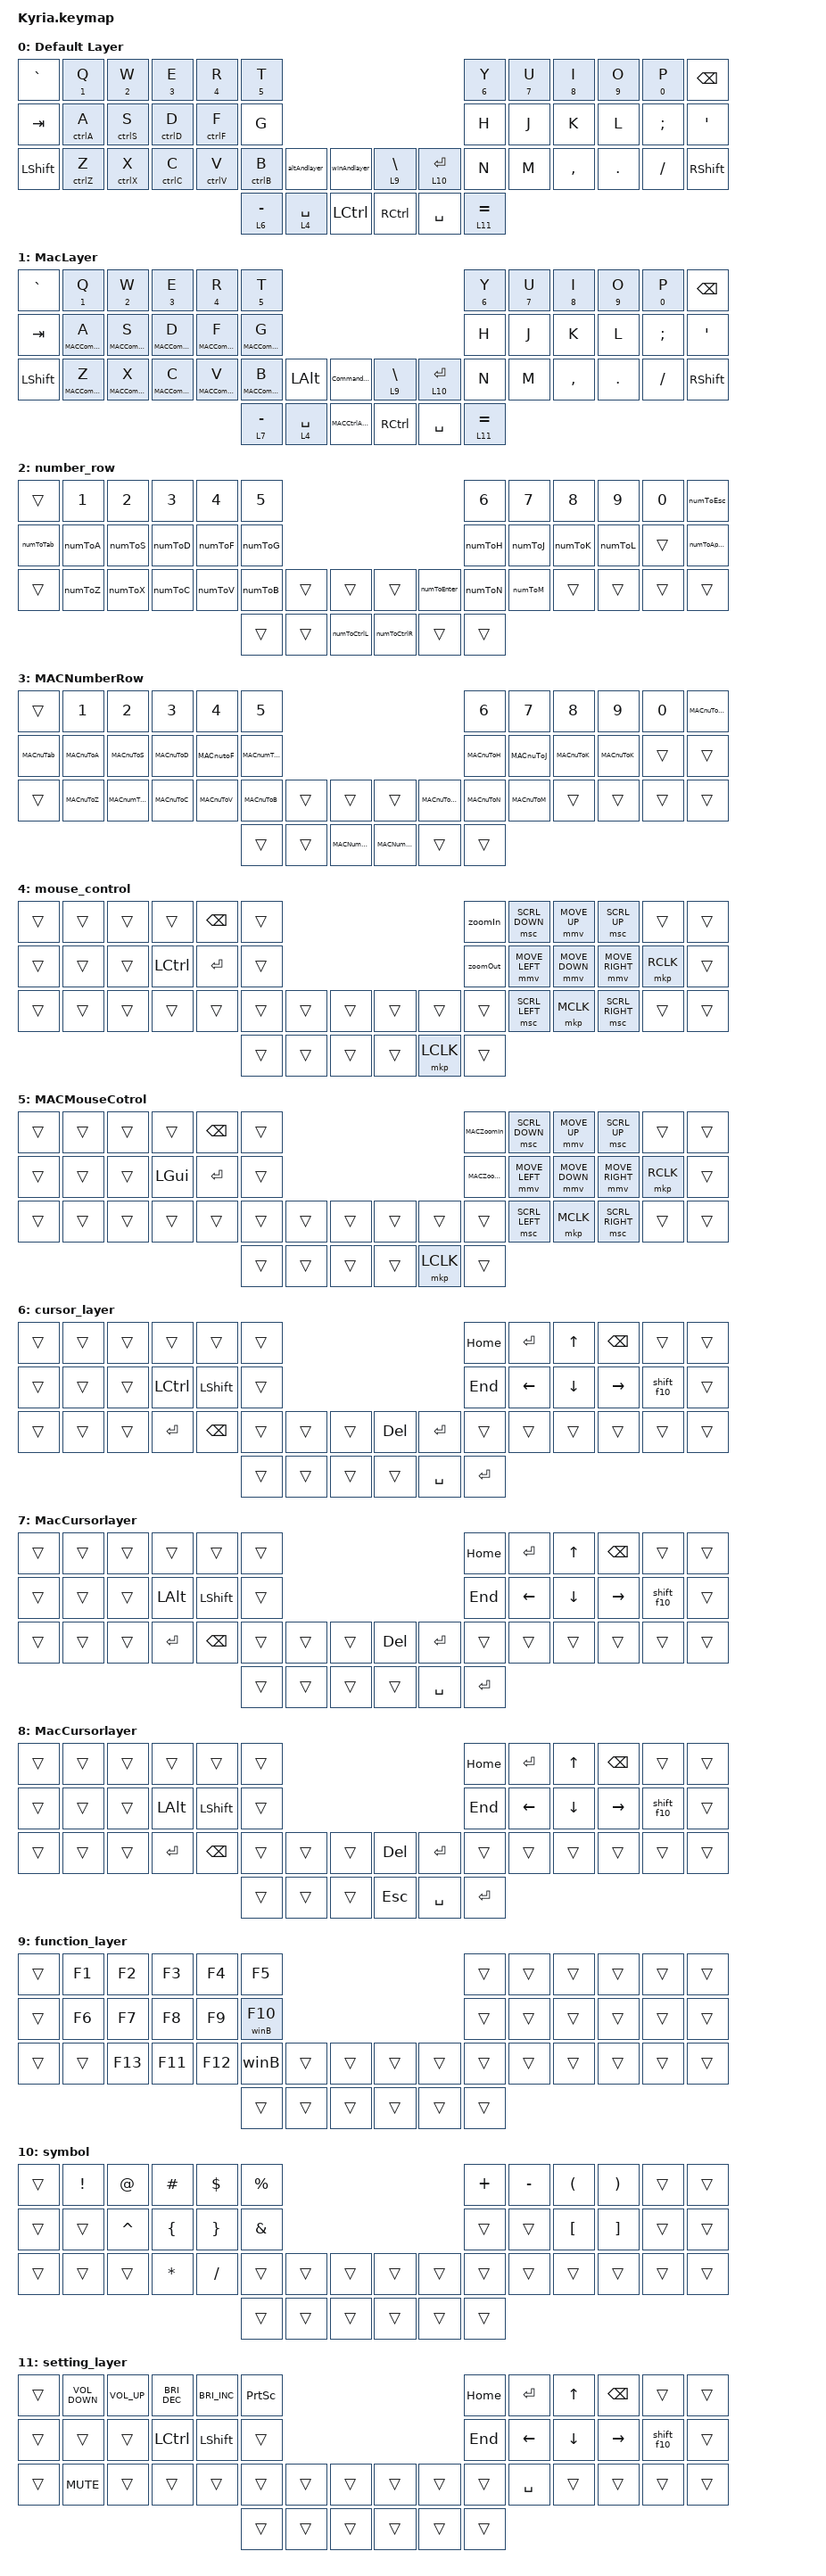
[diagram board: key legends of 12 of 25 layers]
/*
 * Copyright (c) 2020 The ZMK Contributors
 *
 * SPDX-License-Identifier: MIT
 */

#include <input/processors.dtsi>
#include <zephyr/dt-bindings/input/input-event-codes.h>
#include <dt-bindings/zmk/mouse.h>
#include <behaviors/mouse_keys.dtsi>
#include <behaviors.dtsi>
#include <dt-bindings/zmk/bt.h>
#include <dt-bindings/zmk/keys.h>
#include <dt-bindings/zmk/pointing.h>

#define ZMK_POINTING_DEFAULT_MOVE_VAL 1200  // 600
#define ZMK_POINTING_DEFAULT_SCRL_VAL 300   // mousescroll SPEED

&mmv_input_listener { input-processors = <&zip_xy_scaler 2 1>; };

&msc_input_listener { input-processors = <&zip_scroll_scaler 2 1>; };

&msc {
    acceleration-exponent = <1>;      // 0
    time-to-max-speed-ms = <3000>;       // 300
    delay-ms = <0>;                   // 0
};

&mmv {
    time-to-max-speed-ms = <1000>;
    acceleration-exponent = <1>;
    trigger-period-ms = <16>;
};

&soft_off {
    hold-time-ms = <3000>; // Only turn off it the key is held for 3 seconds or longer.
};

&mt { flavor = "tap-preferred"; };

&lt {
    tapping-term-ms = <300>;
    flavor = "balanced";
};

&sk {
    quick-release;
    lazy;
};

/ {
    behaviors {
        Scroll_D_U: Scroll_D_U {
            compatible = "zmk,behavior-sensor-rotate";
            label = "SCROLL_D_U";
            #sensor-binding-cells = <0>;
            bindings = <&msc SCRL_DOWN>, <&msc SCRL_UP>;

            tap-ms = <20>;
        };

        TD01: TD01 {
            compatible = "zmk,behavior-tap-dance";
            label = "TD01";
            #binding-cells = <0>;
            bindings = <&kp MINUS>, <&kp PERIOD>;
        };

        Scroll_U_D: Scroll_U_D {
            compatible = "zmk,behavior-sensor-rotate";
            label = "SCROLL_U_D";
            #sensor-binding-cells = <0>;
            bindings = <&msc SCRL_UP>, <&msc SCRL_DOWN>;

            tap-ms = <20>;
        };

        Scroll_LR: Scroll_LR {
            compatible = "zmk,behavior-sensor-rotate";
            label = "SCROLL_LR";
            #sensor-binding-cells = <0>;
            bindings = <&msc SCRL_LEFT>, <&msc SCRL_RIGHT>;

            tap-ms = <20>;
        };

        Scroll_RL: Scroll_RL {
            compatible = "zmk,behavior-sensor-rotate";
            label = "SCROLL_RL";
            #sensor-binding-cells = <0>;
            bindings = <&msc SCRL_RIGHT>, <&msc SCRL_LEFT>;

            tap-ms = <20>;
        };

        mouse_DU: mouse_DU {
            compatible = "zmk,behavior-sensor-rotate";
            label = "MOUSE_DU";
            #sensor-binding-cells = <0>;
            bindings = <&mmv MOVE_DOWN>, <&mmv MOVE_UP>;
        };

        mouse_RL: mouse_RL {
            compatible = "zmk,behavior-sensor-rotate";
            label = "MOUSE_RL";
            #sensor-binding-cells = <0>;
            bindings = <&mmv MOVE_RIGHT>, <&mmv MOVE_LEFT>;
        };

        cursorandmouse: cursorandmouse_ {
            compatible = "zmk,behavior-tap-dance";
            label = "CURSORANDMOUSE ";
            #binding-cells = <0>;
            bindings = <&lt 22 SPACE>, <&lt 2 SPACE>;

            tapping-term-ms = <400>;
        };

        num_row: num_row {
            compatible = "zmk,behavior-hold-tap";
            label = "NUM_ROW";
            bindings = <&kp>, <&kp>;

            #binding-cells = <2>;
            tapping-term-ms = <300>;
            flavor = "tap-preferred";
        };

        holdCtrlZ: holdCtrlZ {
            compatible = "zmk,behavior-hold-tap";
            label = "HOLDCTRLZ";
            bindings = <&ctrlZ>, <&kp>;

            #binding-cells = <2>;
            tapping-term-ms = <300>;
            flavor = "tap-preferred";
        };

        holdCtrlX: holdCtrlX {
            compatible = "zmk,behavior-hold-tap";
            label = "HOLDCTRLX";
            bindings = <&ctrlX>, <&kp>;

            #binding-cells = <2>;
            tapping-term-ms = <300>;
            flavor = "tap-preferred";
        };

        holdCtrlC: holdCtrlC {
            compatible = "zmk,behavior-hold-tap";
            label = "HOLDCTRLC";
            bindings = <&ctrlC>, <&kp>;

            #binding-cells = <2>;
            tapping-term-ms = <300>;
            flavor = "tap-preferred";
        };

        holdCtrlA: holdCtrlA {
            compatible = "zmk,behavior-hold-tap";
            label = "HOLDCTRLA";
            bindings = <&ctrlA>, <&kp>;

            #binding-cells = <2>;
            tapping-term-ms = <300>;
            flavor = "tap-preferred";
        };

        shiftCtrlTapDance: shiftCtrlTapDance {
            compatible = "zmk,behavior-tap-dance";
            label = "SHIFTCTRLTAPDANCE";
            #binding-cells = <0>;
            bindings = <&kp LEFT_SHIFT>, <&kp LCTRL>;
        };

        shiftEnterTapDance: shiftEnterTapDance {
            compatible = "zmk,behavior-tap-dance";
            label = "SHIFTENTERTAPDANCE";
            #binding-cells = <0>;
            bindings = <&kp RIGHT_SHIFT>, <&kp ENTER>;
        };

        cursorLayerTap: cursorLayerTap {
            compatible = "zmk,behavior-hold-tap";
            label = "CURSORLAYERTAP";
            bindings = <&mo>, <&kp>;

            #binding-cells = <2>;
            tapping-term-ms = <200>;
            flavor = "hold-preferred";
            hold-trigger-key-positions = <32 43 44 33 45 7 8 9 10 11 19 20 21 22 23 35 36 37 38 39 45 6 7 18 19 34 35 14 15 16>;
        };

        WinKey: WinKey {
            compatible = "zmk,behavior-tap-dance";
            label = "WINKEY";
            #binding-cells = <0>;
            bindings = <&winAndlayer>, <&winTabCom>;

            tapping-term-ms = <300>;
        };

        LBracketTapDance: LBracketTapDance {
            compatible = "zmk,behavior-tap-dance";
            label = "LBRACKETTAPDANCE";
            #binding-cells = <0>;
            bindings = <&kp LEFT_BRACKET>, <&kp LEFT_BRACE>;

            tapping-term-ms = <600>;
        };

        RBracketTapDance: RBracketTapDance {
            compatible = "zmk,behavior-tap-dance";
            label = "RBRACKETTAPDANCE";
            #binding-cells = <0>;
            bindings = <&kp LEFT_BRACKET>, <&kp RIGHT_BRACE>;

            tapping-term-ms = <600>;
        };

        F10WinB: F10WinB {
            compatible = "zmk,behavior-hold-tap";
            label = "F10WINB";
            bindings = <&winB>, <&kp>;

            #binding-cells = <2>;
            tapping-term-ms = <200>;
        };

        holdCtrlS: holdCtrlS {
            compatible = "zmk,behavior-hold-tap";
            label = "HOLDCTRLS";
            bindings = <&ctrlS>, <&kp>;

            #binding-cells = <2>;
            tapping-term-ms = <300>;
            flavor = "tap-preferred";
        };

        holdCtrlV: holdCtrlV {
            compatible = "zmk,behavior-hold-tap";
            label = "HOLDCTRLV";
            bindings = <&ctrlV>, <&kp>;

            #binding-cells = <2>;
            tapping-term-ms = <300>;
            flavor = "tap-preferred";
        };

        symbolLayertap: symbolLayertap {
            compatible = "zmk,behavior-hold-tap";
            label = "SYMBOLLAYERTAP";
            bindings = <&mo>, <&kp>;

            #binding-cells = <2>;
            tapping-term-ms = <200>;
            hold-trigger-key-positions = <1 2 3 4 5 16 15 19 18 6 7 8 20 9 21 27 28 14 17>;
            flavor = "balanced";
        };

        holdCtrlF: holdCtrlF {
            compatible = "zmk,behavior-hold-tap";
            label = "HOLDCTRLF";
            bindings = <&ctrlF>, <&kp>;

            #binding-cells = <2>;
            tapping-term-ms = <300>;
            flavor = "tap-preferred";
        };

        holdCtrlD: holdCtrlD {
            compatible = "zmk,behavior-hold-tap";
            label = "HOLDCTRLD";
            bindings = <&ctrlD>, <&kp>;

            #binding-cells = <2>;
            tapping-term-ms = <300>;
            flavor = "tap-preferred";
        };

        mouseLayerTap: mouseLayerTap {
            compatible = "zmk,behavior-hold-tap";
            label = "MOUSELAYERTAP";
            bindings = <&mo>, <&kp>;

            #binding-cells = <2>;
            tapping-term-ms = <200>;
            hold-trigger-key-positions = <16 1 2 3 4 13 14 15 16 25 26 27 28>;
            flavor = "balanced";
        };

        altLayerBehave: altLayerBehave {
            compatible = "zmk,behavior-hold-tap";
            label = "ALTLAYERBEHAVE";
            bindings = <&altAndlayer>, <&kp>;

            #binding-cells = <2>;
            tapping-term-ms = <200>;
            hold-trigger-key-positions = <3 4 2>;
            flavor = "balanced";
        };

        holdCtrlB: holdCtrlB {
            compatible = "zmk,behavior-hold-tap";
            label = "HOLDCTRLB";
            bindings = <&ctrlB>, <&kp>;

            #binding-cells = <2>;
            tapping-term-ms = <300>;
            flavor = "tap-preferred";
        };

        functionLayerTap: functionLayerTap {
            compatible = "zmk,behavior-hold-tap";
            label = "FUNCTIONLAYERTAP";
            bindings = <&mo>, <&kp>;

            #binding-cells = <2>;
            tapping-term-ms = <200>;
            hold-trigger-key-positions = <1 2 3 4 13 14 15 16 25 26 27 28 16 17 28 29 5>;
            flavor = "hold-preferred";
        };

        MACHoldCommandA: MACHoldCommandA {
            compatible = "zmk,behavior-hold-tap";
            label = "MACHOLDCOMMANDA";
            bindings = <&MACCommandA>, <&kp>;

            #binding-cells = <2>;
            tapping-term-ms = <300>;
            flavor = "tap-preferred";
        };

        MACHoldCommandZ: MACHoldCommandZ {
            compatible = "zmk,behavior-hold-tap";
            label = "MACHOLDCOMMANDZ";
            bindings = <&MACCommandZ>, <&kp>;

            #binding-cells = <2>;
            tapping-term-ms = <300>;
            flavor = "tap-preferred";
        };

        MACHoldCommandS: MACHoldCommandS {
            compatible = "zmk,behavior-hold-tap";
            label = "MACHOLDCOMMANDS";
            bindings = <&MACCommandS>, <&kp>;

            #binding-cells = <2>;
            tapping-term-ms = <300>;
            flavor = "tap-preferred";
        };

        MACHoldCommandX: MACHoldCommandX {
            compatible = "zmk,behavior-hold-tap";
            label = "MACHOLDCOMMANDX";
            bindings = <&MACCommandX>, <&kp>;

            #binding-cells = <2>;
            tapping-term-ms = <300>;
            flavor = "tap-preferred";
        };

        MACHoldCommandD: MACHoldCommandD {
            compatible = "zmk,behavior-hold-tap";
            label = "MACHOLDCOMMANDD";
            bindings = <&MACCommandD>, <&kp>;

            #binding-cells = <2>;
            tapping-term-ms = <300>;
            flavor = "tap-preferred";
        };

        MACHoldCommandC: MACHoldCommandC {
            compatible = "zmk,behavior-hold-tap";
            label = "MACHOLDCOMMANDC";
            bindings = <&MACCommandC>, <&kp>;

            #binding-cells = <2>;
            tapping-term-ms = <300>;
            flavor = "tap-preferred";
        };

        MACHoldCommandF: MACHoldCommandF {
            compatible = "zmk,behavior-hold-tap";
            label = "MACHOLDCOMMANDF";
            bindings = <&MACCommandF>, <&kp>;

            #binding-cells = <2>;
            tapping-term-ms = <300>;
            flavor = "tap-preferred";
        };

        MACHoldCommandV: MACHoldCommandV {
            compatible = "zmk,behavior-hold-tap";
            label = "MACHOLDCOMMANDV";
            bindings = <&MACCommandV>, <&kp>;

            #binding-cells = <2>;
            tapping-term-ms = <300>;
            flavor = "tap-preferred";
        };

        MACHoldCommandG: MACHoldCommandG {
            compatible = "zmk,behavior-hold-tap";
            label = "MACHOLDCOMMANDG";
            bindings = <&MACCommandG>, <&kp>;

            #binding-cells = <2>;
            tapping-term-ms = <300>;
            flavor = "tap-preferred";
        };

        MACHoldCommandB: MACHoldCommandB {
            compatible = "zmk,behavior-hold-tap";
            label = "MACHOLDCOMMANDB";
            bindings = <&MACCommandB>, <&kp>;

            #binding-cells = <2>;
            tapping-term-ms = <300>;
            flavor = "tap-preferred";
        };

        ToggleOnOnly: ToggleOnOnly {
            compatible = "zmk,behavior-toggle-layer";
            label = "TOGGLEONONLY";
            #binding-cells = <1>;
        };

        ToggleOffOnly: ToggleOffOnly {
            compatible = "zmk,behavior-toggle-layer";
            label = "TOGGLEOFFONLY";
            #binding-cells = <1>;
            toggle-mode = "off";
        };
    };

    combos {
        compatible = "zmk,combos";

        ctrl-shift-combo {
            bindings = <&ctrlShiftCombo>;
            key-positions = <24 25>;
            layers = <0 2 10>;
        };

        one-keyboard-control {
            bindings = <&to 22>;
            key-positions = <12 0>;
        };

        bt_cl_all {
            bindings = <&bt BT_CLR_ALL>;
            key-positions = <29 30>;
        };

        bt_next {
            bindings = <&bt BT_NXT>;
            key-positions = <43 33>;
            timeout-ms = <300>;
        };

        number_row_combo {
            bindings = <&tog 2>;
            key-positions = <16 19>;
            layers = <0 2>;
            require-prior-idle-ms = <150>;
        };

        toggle_mouse_L {
            bindings = <&tog 4>;
            key-positions = <40 41>;
            layers = <0 4>;
        };

        esc {
            bindings = <&numToEsc>;
            key-positions = <15 41>;
            timeout-ms = <400>;
            layers = <0 2 4>;
            slow-release;
            require-prior-idle-ms = <150>;
        };

        combo_left_shift {
            bindings = <&kp LEFT_SHIFT>;
            key-positions = <15 16>;
            timeout-ms = <200>;
            layers = <0 10 2 16 14 11 1 3>;
            require-prior-idle-ms = <150>;
        };

        combo_right_shift {
            bindings = <&kp RIGHT_SHIFT>;
            key-positions = <19 20>;
            timeout-ms = <200>;
            layers = <0 10 2 16 14 1 3>;
            require-prior-idle-ms = <150>;
        };

        capslook {
            bindings = <&kp CAPSLOCK>;
            key-positions = <15 20>;
            layers = <0 2 1 3>;
            require-prior-idle-ms = <150>;
        };

        firstP_gaming {
            bindings = <&tog 23>;
            key-positions = <12 24>;
            layers = <0 2 10 23>;
        };

        togKbMouse {
            bindings = <&tog 13>;
            key-positions = <42 31>;
            layers = <0 2 13 1 3>;
        };

        alt_tab_combo {
            bindings = <&alt_tab>;
            key-positions = <30 3>;
            layers = <0 2 6>;
        };

        altF4Combo {
            bindings = <&altF4d>;
            key-positions = <4 30>;
            layers = <0 2>;
        };

        winBCombo {
            bindings = <&winB>;
            key-positions = <31 29>;
            layers = <0 2>;
        };

        winTabCombo {
            bindings = <&winTabCom>;
            key-positions = <31 4>;
            layers = <0 14 1>;
        };

        bluetoothSetting {
            bindings = <&mo 24>;
            key-positions = <12 24>;
        };

        toMacLayerComb {
            bindings = <&tog 1>;
            key-positions = <29 40>;
            layers = <0 2>;
        };

        MACComboType {
            bindings = <&MACMacroType>;
            key-positions = <40 28>;
            layers = <1>;
        };

        WINComboType {
            bindings = <&WINMacroType>;
            key-positions = <40 28>;
            layers = <0>;
        };

        toWINLayerComb {
            bindings = <&to 0>;
            key-positions = <29 40>;
            layers = <1 3>;
        };

        MACNumberRowCombo {
            bindings = <&tog 3>;
            key-positions = <16 19>;
            layers = <1 3>;
        };

        MACEsc {
            bindings = <&MACNumToEsc>;
            key-positions = <15 41>;
            timeout-ms = <400>;
            slow-release;
            layers = <1 3 5>;
        };

        EnterComb {
            bindings = <&kp ENTER>;
            key-positions = <20 44>;
            layers = <0 2 4 6 1 3 5 7>;
            slow-release;
            require-prior-idle-ms = <150>;
        };

        MACMouseControlL {
            bindings = <&tog 5>;
            key-positions = <41 40>;
            layers = <1 5>;
        };

        toggle_mouse_control_r {
            bindings = <&tog 4>;
            key-positions = <44 45>;
            layers = <0 4>;
        };

        MACMouseControlR {
            bindings = <&tog 5>;
            key-positions = <44 45>;
            layers = <1 5>;
        };
    };

    macros {
        alt_tab: alt_tab {
            compatible = "zmk,behavior-macro";
            #binding-cells = <0>;
            bindings =
                <&macro_press>,
                <&kp LEFT_ALT>,
                <&macro_tap>,
                <&kp TAB>,
                <&macro_release>,
                <&kp LEFT_ALT>;

            label = "ALT_TAB";
        };

        ctrlShiftCombo: ctrlShiftCombo {
            compatible = "zmk,behavior-macro";
            #binding-cells = <0>;
            bindings =
                <&macro_press>,
                <&kp LCTRL &kp LEFT_SHIFT>,
                <&macro_release>,
                <&kp LCTRL &kp LEFT_SHIFT>;

            label = "CTRLSHIFTCOMBO";
        };

        ctrl_a: ctrl_a {
            compatible = "zmk,behavior-macro";
            #binding-cells = <0>;
            bindings =
                <&macro_press>,
                <&kp LCTRL>,
                <&macro_tap>,
                <&kp A>,
                <&macro_release>,
                <&kp LCTRL>;

            label = "CTRL_A";
        };

        delete_word: delete_word {
            compatible = "zmk,behavior-macro";
            #binding-cells = <0>;
            bindings =
                <&macro_press>,
                <&kp LCTRL &kp LEFT_SHIFT>,
                <&macro_tap>,
                <&kp LEFT_ARROW &kp BACKSPACE>,
                <&macro_release>,
                <&kp LCTRL &kp LEFT_SHIFT>;

            label = "DELETE_WORD";
        };

        hi_prv: hi_prv {
            compatible = "zmk,behavior-macro";
            #binding-cells = <0>;
            bindings =
                <&macro_press>,
                <&kp LCTRL &kp LEFT_SHIFT>,
                <&macro_tap>,
                <&kp LEFT_ARROW>,
                <&macro_release>,
                <&kp LCTRL &kp LEFT_SHIFT>;

            label = "HI_PRV";
        };

        shift_f10: shift_f10 {
            compatible = "zmk,behavior-macro";
            #binding-cells = <0>;
            bindings =
                <&macro_press>,
                <&kp LEFT_SHIFT>,
                <&macro_tap>,
                <&kp F10>,
                <&macro_release>,
                <&kp LEFT_SHIFT>;

            label = "SHIFT_F10";
        };

        ctrlX: ctrlX {
            compatible = "zmk,behavior-macro";
            #binding-cells = <0>;
            bindings =
                <&macro_press>,
                <&kp LCTRL>,
                <&macro_tap>,
                <&kp X>,
                <&macro_release>,
                <&kp LCTRL>;

            label = "CTRLX";
        };

        ctrlC: ctrlC {
            compatible = "zmk,behavior-macro";
            #binding-cells = <0>;
            bindings =
                <&macro_press>,
                <&kp LCTRL>,
                <&macro_tap>,
                <&kp C>,
                <&macro_release>,
                <&kp LCTRL>;

            label = "CTRLC";
        };

        ctrlV: ctrlV {
            compatible = "zmk,behavior-macro";
            #binding-cells = <0>;
            bindings =
                <&macro_press>,
                <&kp LCTRL>,
                <&macro_tap>,
                <&kp V>,
                <&macro_release>,
                <&kp LCTRL>;

            label = "CTRLV";
        };

        winAndlayer: win_layer {
            compatible = "zmk,behavior-macro";
            #binding-cells = <0>;
            bindings =
                <&macro_tap>,
                <&to 0>,
                <&macro_press>,
                <&kp LEFT_GUI &mo 14>,
                <&macro_pause_for_release>,
                <&macro_release>,
                <&kp LEFT_GUI &mo 14>;

            label = "WIN_LAYER";
            wait-ms = <1>;
        };

        altAndlayer: alt_layer {
            compatible = "zmk,behavior-macro";
            #binding-cells = <0>;
            bindings =
                <&macro_tap>,
                <&to 0>,
                <&macro_press>,
                <&kp LEFT_ALT &mo 16>,
                <&macro_pause_for_release>,
                <&macro_release>,
                <&kp LEFT_ALT &mo 16>;

            label = "ALT_LAYER";
            wait-ms = <1>;
        };

        ctrlZ: ctrlZ {
            compatible = "zmk,behavior-macro";
            #binding-cells = <0>;
            bindings =
                <&macro_press>,
                <&kp LCTRL>,
                <&macro_tap>,
                <&kp Z>,
                <&macro_release>,
                <&kp LCTRL>;

            label = "CTRLZ";
        };

        ctrlY: ctrlY {
            compatible = "zmk,behavior-macro";
            #binding-cells = <0>;
            bindings =
                <&macro_press>,
                <&kp LCTRL>,
                <&macro_tap>,
                <&kp Y>,
                <&macro_release>,
                <&kp LCTRL>;

            label = "CTRLY";
        };

        altF4d: altF4d {
            compatible = "zmk,behavior-macro";
            #binding-cells = <0>;
            bindings =
                <&macro_press>,
                <&kp LEFT_ALT>,
                <&macro_tap>,
                <&kp F4>,
                <&macro_release>,
                <&kp LEFT_ALT>;

            label = "ALTF4D";
        };

        winB: winB {
            compatible = "zmk,behavior-macro";
            #binding-cells = <0>;
            bindings =
                <&macro_press>,
                <&kp LEFT_GUI>,
                <&macro_tap>,
                <&kp B>,
                <&macro_release>,
                <&kp LEFT_GUI>;

            label = "WINB";
        };

        RCtrlToDefault: ctrlToDefault {
            compatible = "zmk,behavior-macro";
            #binding-cells = <0>;
            bindings =
                <&macro_tap>,
                <&to 0>,
                <&macro_press>,
                <&kp RCTRL>,
                <&macro_pause_for_release>,
                <&macro_release>,
                <&kp RCTRL>;

            label = "CTRLTODEFAULT";
        };

        LCtrlToDefault: LCtrlToDefault {
            compatible = "zmk,behavior-macro";
            #binding-cells = <0>;
            bindings =
                <&macro_tap>,
                <&to 0>,
                <&macro_press>,
                <&kp LCTRL>,
                <&macro_pause_for_release>,
                <&macro_release>,
                <&kp LCTRL>;

            label = "LCTRLTODEFAULT";
        };

        winTabCom: winTabCom {
            compatible = "zmk,behavior-macro";
            #binding-cells = <0>;
            bindings =
                <&macro_press>,
                <&kp LEFT_GUI>,
                <&macro_tap>,
                <&kp TAB>,
                <&macro_release>,
                <&kp LEFT_GUI>;

            label = "WINTABCOM";
        };

        CursorHoldControl: CursorHoldControl {
            compatible = "zmk,behavior-macro";
            #binding-cells = <0>;
            bindings =
                <&macro_press>,
                <&kp LCTRL &mo 6>,
                <&macro_pause_for_release>,
                <&macro_release>,
                <&kp LCTRL &mo 6>;

            label = "CURSORHOLDCONTROL";
        };

        CursorHoldShift: CursorHoldShift {
            compatible = "zmk,behavior-macro";
            #binding-cells = <0>;
            bindings =
                <&macro_press>,
                <&kp LEFT_SHIFT &mo 6>,
                <&macro_pause_for_release>,
                <&macro_release>,
                <&kp LEFT_SHIFT &mo 6>;

            label = "CURSORHOLDSHIFT";
        };

        CursorHoldCtrlShift: CursorHoldCtrlShift {
            compatible = "zmk,behavior-macro";
            #binding-cells = <0>;
            bindings =
                <&macro_press>,
                <&kp LCTRL &kp LEFT_SHIFT &mo 6>,
                <&macro_pause_for_release>,
                <&macro_release>,
                <&kp LCTRL &kp LEFT_SHIFT &mo 6>;

            label = "CURSORHOLDCTRLSHIFT";
        };

        ctrlA: ctrlA {
            compatible = "zmk,behavior-macro";
            #binding-cells = <0>;
            bindings =
                <&macro_press>,
                <&kp LCTRL>,
                <&macro_tap>,
                <&kp A>,
                <&macro_release>,
                <&kp LCTRL>;

            label = "CTRLA";
        };

        ctrlS: ctrlS {
            compatible = "zmk,behavior-macro";
            #binding-cells = <0>;
            bindings =
                <&macro_press>,
                <&kp LCTRL>,
                <&macro_tap>,
                <&kp S>,
                <&macro_release>,
                <&kp LCTRL>;

            label = "CTRLS";
        };

        numToSemicolon: numToDefaultKey {
            compatible = "zmk,behavior-macro";
            #binding-cells = <0>;
            bindings =
                <&macro_tap>,
                <&to 0>,
                <&macro_press>,
                <&kp SEMI>,
                <&macro_pause_for_release>,
                <&macro_release>,
                <&kp SEMI>;

            label = "NUMTODEFAULTKEY";
        };

        numToSlash: numToDivide {
            compatible = "zmk,behavior-macro";
            #binding-cells = <0>;
            bindings =
                <&macro_tap>,
                <&to 0>,
                <&macro_press>,
                <&kp SLASH>,
                <&macro_pause_for_release>,
                <&macro_release>,
                <&kp SLASH>;

            label = "NUMTODIVIDE";
        };

        numToL: numToL {
            compatible = "zmk,behavior-macro";
            #binding-cells = <0>;
            bindings =
                <&macro_tap>,
                <&to 0>,
                <&macro_press>,
                <&kp L>,
                <&macro_pause_for_release>,
                <&macro_release>,
                <&kp L>;

            label = "NUMTOL";
        };

        numToDot: numToGreater {
            compatible = "zmk,behavior-macro";
            #binding-cells = <0>;
            bindings =
                <&macro_tap>,
                <&to 0>,
                <&macro_press>,
                <&kp DOT>,
                <&macro_pause_for_release>,
                <&macro_release>,
                <&kp DOT>;

            label = "NUMTOGREATER";
        };

        numToComma: numToColon {
            compatible = "zmk,behavior-macro";
            #binding-cells = <0>;
            bindings =
                <&macro_tap>,
                <&to 0>,
                <&macro_press>,
                <&kp COMMA>,
                <&macro_pause_for_release>,
                <&macro_release>,
                <&kp COMMA>;

            label = "NUMTOCOLON";
        };

        numToK: numToK {
            compatible = "zmk,behavior-macro";
            #binding-cells = <0>;
            bindings =
                <&macro_tap>,
                <&to 0>,
                <&macro_press>,
                <&kp K>,
                <&macro_pause_for_release>,
                <&macro_release>,
                <&kp K>;

            label = "NUMTOK";
        };

        numToJ: numToJ {
            compatible = "zmk,behavior-macro";
            #binding-cells = <0>;
            bindings =
                <&macro_tap>,
                <&to 0>,
                <&macro_press>,
                <&kp J>,
                <&macro_pause_for_release>,
                <&macro_release>,
                <&kp J>;

            label = "NUMTOJ";
        };

        numToM: numToM {
            compatible = "zmk,behavior-macro";
            #binding-cells = <0>;
            bindings =
                <&macro_tap>,
                <&to 0>,
                <&macro_press>,
                <&kp M>,
                <&macro_pause_for_release>,
                <&macro_release>,
                <&kp M>;

            label = "NUMTOM";
        };

        numToH: numToH {
            compatible = "zmk,behavior-macro";
            #binding-cells = <0>;
            bindings =
                <&macro_tap>,
                <&to 0>,
                <&macro_press>,
                <&kp H>,
                <&macro_pause_for_release>,
                <&macro_release>,
                <&kp H>;

            label = "NUMTOH";
        };

        numToN: numToN {
            compatible = "zmk,behavior-macro";
            #binding-cells = <0>;
            bindings =
                <&macro_tap>,
                <&to 0>,
                <&macro_press>,
                <&kp N>,
                <&macro_pause_for_release>,
                <&macro_release>,
                <&kp N>;

            label = "NUMTON";
        };

        numToEsc: numToEsc {
            compatible = "zmk,behavior-macro";
            #binding-cells = <0>;
            bindings =
                <&macro_tap>,
                <&to 0>,
                <&macro_press>,
                <&kp ESCAPE>,
                <&macro_pause_for_release>,
                <&macro_release>,
                <&kp ESCAPE>;

            label = "NUMTOESC";
        };

        numToA: numToA {
            compatible = "zmk,behavior-macro";
            #binding-cells = <0>;
            bindings =
                <&macro_tap>,
                <&to 0>,
                <&macro_press>,
                <&kp A>,
                <&macro_pause_for_release>,
                <&macro_release>,
                <&kp A>;

            label = "NUMTOA";
        };

        numToZ: numToZ {
            compatible = "zmk,behavior-macro";
            #binding-cells = <0>;
            bindings =
                <&macro_tap>,
                <&to 0>,
                <&macro_press>,
                <&kp Z>,
                <&macro_pause_for_release>,
                <&macro_release>,
                <&kp Z>;

            label = "NUMTOZ";
        };

        numToS: numToS {
            compatible = "zmk,behavior-macro";
            #binding-cells = <0>;
            bindings =
                <&macro_tap>,
                <&to 0>,
                <&macro_press>,
                <&kp S>,
                <&macro_pause_for_release>,
                <&macro_release>,
                <&kp S>;

            label = "NUMTOS";
        };

        numToX: numToX {
            compatible = "zmk,behavior-macro";
            #binding-cells = <0>;
            bindings =
                <&macro_tap>,
                <&to 0>,
                <&macro_press>,
                <&kp X>,
                <&macro_pause_for_release>,
                <&macro_release>,
                <&kp X>;

            label = "NUMTOX";
        };

        numToD: numToD {
            compatible = "zmk,behavior-macro";
            #binding-cells = <0>;
            bindings =
                <&macro_tap>,
                <&to 0>,
                <&macro_press>,
                <&kp D>,
                <&macro_pause_for_release>,
                <&macro_release>,
                <&kp D>;

            label = "NUMTOD";
        };

        numToC: numToC {
            compatible = "zmk,behavior-macro";
            #binding-cells = <0>;
            bindings =
                <&macro_tap>,
                <&to 0>,
                <&macro_press>,
                <&kp C>,
                <&macro_pause_for_release>,
                <&macro_release>,
                <&kp C>;

            label = "NUMTOC";
        };

        numToF: numToF {
            compatible = "zmk,behavior-macro";
            #binding-cells = <0>;
            bindings =
                <&macro_tap>,
                <&to 0>,
                <&macro_press>,
                <&kp F>,
                <&macro_pause_for_release>,
                <&macro_release>,
                <&kp F>;

            label = "NUMTOF";
        };

        numToG: numToG {
            compatible = "zmk,behavior-macro";
            #binding-cells = <0>;
            bindings =
                <&macro_tap>,
                <&to 0>,
                <&macro_press>,
                <&kp G>,
                <&macro_pause_for_release>,
                <&macro_release>,
                <&kp G>;

            label = "NUMTOG";
        };

        numToB: numToB {
            compatible = "zmk,behavior-macro";
            #binding-cells = <0>;
            bindings =
                <&macro_tap>,
                <&to 0>,
                <&macro_press>,
                <&kp B>,
                <&macro_pause_for_release>,
                <&macro_release>,
                <&kp B>;

            label = "NUMTOB";
        };

        numToV: numToV {
            compatible = "zmk,behavior-macro";
            #binding-cells = <0>;
            bindings =
                <&macro_tap>,
                <&to 0>,
                <&macro_press>,
                <&kp V>,
                <&macro_pause_for_release>,
                <&macro_release>,
                <&kp V>;

            label = "NUMTOV";
        };

        numToApostrophe: numToApostrophe {
            compatible = "zmk,behavior-macro";
            #binding-cells = <0>;
            bindings =
                <&macro_tap>,
                <&to 0>,
                <&macro_press>,
                <&kp SQT>,
                <&macro_pause_for_release>,
                <&macro_release>,
                <&kp SQT>;

            label = "NUMTOAPOSTROPHE";
        };

        numToTab: numToTab {
            compatible = "zmk,behavior-macro";
            #binding-cells = <0>;
            bindings =
                <&macro_tap>,
                <&to 0>,
                <&macro_press>,
                <&kp TAB>,
                <&macro_pause_for_release>,
                <&macro_release>,
                <&kp TAB>;

            label = "NUMTOTAB";
        };

        numToCtrlL: numToCtrlL {
            compatible = "zmk,behavior-macro";
            #binding-cells = <0>;
            bindings =
                <&macro_tap>,
                <&to 0>,
                <&macro_press>,
                <&kp LCTRL>,
                <&macro_pause_for_release>,
                <&macro_release>,
                <&kp LCTRL>;

            label = "NUMTOCTRLL";
        };

        numToCtrlR: numToCtrlR {
            compatible = "zmk,behavior-macro";
            #binding-cells = <0>;
            bindings =
                <&macro_tap>,
                <&to 0>,
                <&macro_press>,
                <&kp RCTRL>,
                <&macro_pause_for_release>,
                <&macro_release>,
                <&kp RCTRL>;

            label = "NUMTOCTRLR";
        };

        numToEnter: numToEnter {
            compatible = "zmk,behavior-macro";
            #binding-cells = <0>;
            bindings =
                <&macro_tap>,
                <&to 0>,
                <&macro_press>,
                <&kp ENTER>,
                <&macro_pause_for_release>,
                <&macro_release>,
                <&kp ENTER>;

            label = "NUMTOENTER";
        };

        ctrlF: ctrlF {
            compatible = "zmk,behavior-macro";
            #binding-cells = <0>;
            bindings =
                <&macro_press>,
                <&kp LCTRL>,
                <&macro_tap>,
                <&kp F>,
                <&macro_release>,
                <&kp LCTRL>;

            label = "CTRLF";
        };

        ctrlD: ctrlD {
            compatible = "zmk,behavior-macro";
            #binding-cells = <0>;
            bindings =
                <&macro_press>,
                <&kp LCTRL>,
                <&macro_tap>,
                <&kp D>,
                <&macro_release>,
                <&kp LCTRL>;

            label = "CTRLD";
        };

        zoomIn: zoomIn {
            compatible = "zmk,behavior-macro";
            #binding-cells = <0>;
            bindings =
                <&macro_press>,
                <&kp LCTRL &msc SCRL_UP>,
                <&macro_pause_for_release>,
                <&macro_release>,
                <&kp LCTRL &msc SCRL_UP>;

            label = "ZOOMIN";
            wait-ms = <50>;
        };

        zoomOut: zoomOut {
            compatible = "zmk,behavior-macro";
            #binding-cells = <0>;
            bindings =
                <&macro_press>,
                <&kp LCTRL &msc SCRL_DOWN>,
                <&macro_pause_for_release>,
                <&macro_release>,
                <&kp LCTRL &msc SCRL_DOWN>;

            label = "ZOOMOUT";
            wait-ms = <50>;
        };

        ctrlB: ctrlB {
            compatible = "zmk,behavior-macro";
            #binding-cells = <0>;
            bindings =
                <&macro_press>,
                <&kp LCTRL>,
                <&macro_tap>,
                <&kp B>,
                <&macro_release>,
                <&kp LCTRL>;

            label = "CTRLB";
        };

        MACCommandA: MACCommandA {
            compatible = "zmk,behavior-macro";
            #binding-cells = <0>;
            bindings =
                <&macro_press>,
                <&kp LEFT_COMMAND>,
                <&macro_tap>,
                <&kp A>,
                <&macro_release>,
                <&kp LEFT_COMMAND>;

            label = "MACCOMMANDA";
        };

        MACCommandZ: MACCommandZ {
            compatible = "zmk,behavior-macro";
            #binding-cells = <0>;
            bindings =
                <&macro_press>,
                <&kp LEFT_COMMAND>,
                <&macro_tap>,
                <&kp Z>,
                <&macro_release>,
                <&kp LEFT_COMMAND>;

            label = "MACCOMMANDZ";
        };

        MACCommandS: MACCommandS {
            compatible = "zmk,behavior-macro";
            #binding-cells = <0>;
            bindings =
                <&macro_press>,
                <&kp LEFT_COMMAND>,
                <&macro_tap>,
                <&kp S>,
                <&macro_release>,
                <&kp LEFT_COMMAND>;

            label = "MACCOMMANDS";
        };

        MACCommandX: MACCommandX {
            compatible = "zmk,behavior-macro";
            #binding-cells = <0>;
            bindings =
                <&macro_press>,
                <&kp LEFT_COMMAND>,
                <&macro_tap>,
                <&kp X>,
                <&macro_release>,
                <&kp LEFT_COMMAND>;

            label = "MACCOMMANDX";
        };

        MACCommandD: MACCommandD {
            compatible = "zmk,behavior-macro";
            #binding-cells = <0>;
            bindings =
                <&macro_press>,
                <&kp LEFT_COMMAND>,
                <&macro_tap>,
                <&kp D>,
                <&macro_release>,
                <&kp LEFT_COMMAND>;

            label = "MACCOMMANDD";
        };

        MACCommandC: MACCommandC {
            compatible = "zmk,behavior-macro";
            #binding-cells = <0>;
            bindings =
                <&macro_press>,
                <&kp LEFT_COMMAND>,
                <&macro_tap>,
                <&kp C>,
                <&macro_release>,
                <&kp LEFT_COMMAND>;

            label = "MACCOMMANDC";
        };

        MACCommandF: MACCommandF {
            compatible = "zmk,behavior-macro";
            #binding-cells = <0>;
            bindings =
                <&macro_press>,
                <&kp LEFT_COMMAND>,
                <&macro_tap>,
                <&kp F>,
                <&macro_release>,
                <&kp LEFT_COMMAND>;

            label = "MACCOMMANDF";
        };

        MACCommandV: MACCommandV {
            compatible = "zmk,behavior-macro";
            #binding-cells = <0>;
            bindings =
                <&macro_press>,
                <&kp LEFT_COMMAND>,
                <&macro_tap>,
                <&kp V>,
                <&macro_release>,
                <&kp LEFT_COMMAND>;

            label = "MACCOMMANDV";
        };

        MACCommandG: MACCommandG {
            compatible = "zmk,behavior-macro";
            #binding-cells = <0>;
            bindings =
                <&macro_press>,
                <&kp LEFT_COMMAND>,
                <&macro_tap>,
                <&kp G>,
                <&macro_release>,
                <&kp LEFT_COMMAND>;

            label = "MACCOMMANDG";
        };

        MACCommandB: MACCommandB {
            compatible = "zmk,behavior-macro";
            #binding-cells = <0>;
            bindings =
                <&macro_press>,
                <&kp LEFT_COMMAND>,
                <&macro_tap>,
                <&kp B>,
                <&macro_release>,
                <&kp LEFT_COMMAND>;

            label = "MACCOMMANDB";
        };

        MACMacroType: MACMacroType {
            compatible = "zmk,behavior-macro";
            #binding-cells = <0>;
            bindings =
                <&macro_press>,
                <&kp LEFT_SHIFT>,
                <&macro_tap>,
                <&kp M &kp A &kp C>,
                <&macro_release>,
                <&kp LEFT_SHIFT>;

            label = "MACMACROTYPE";
        };

        WINMacroType: WINMacroType {
            compatible = "zmk,behavior-macro";
            #binding-cells = <0>;
            bindings =
                <&macro_press>,
                <&kp LEFT_SHIFT>,
                <&macro_tap>,
                <&kp W &kp I &kp N>,
                <&macro_release>,
                <&kp LEFT_SHIFT>;

            label = "WINMACROTYPE";
        };

        MACZoomIn: MACZoomIn {
            compatible = "zmk,behavior-macro";
            #binding-cells = <0>;
            bindings =
                <&macro_press>,
                <&kp LEFT_COMMAND &kp EQUAL>,
                <&macro_pause_for_release>,
                <&macro_release>,
                <&kp LEFT_COMMAND &kp EQUAL>;

            label = "MACZOOMIN";
            wait-ms = <50>;
        };

        MACZoomOut: MACZoomOut {
            compatible = "zmk,behavior-macro";
            #binding-cells = <0>;
            bindings =
                <&macro_press>,
                <&kp LEFT_COMMAND &kp MINUS>,
                <&macro_pause_for_release>,
                <&macro_release>,
                <&kp LEFT_COMMAND &kp MINUS>;

            label = "MACZOOMOUT";
            wait-ms = <50>;
        };

        MACnuToL: MACnuToTab {
            compatible = "zmk,behavior-macro";
            #binding-cells = <0>;
            bindings =
                <&macro_tap>,
                <&to 1>,
                <&macro_press>,
                <&kp L>,
                <&macro_pause_for_release>,
                <&macro_release>,
                <&kp L>;

            label = "MACNUTOTAB";
        };

        MACnuToK: MACnuToK {
            compatible = "zmk,behavior-macro";
            #binding-cells = <0>;
            bindings =
                <&macro_tap>,
                <&to 1>,
                <&macro_press>,
                <&kp K>,
                <&macro_pause_for_release>,
                <&macro_release>,
                <&kp K>;

            label = "MACNUTOK";
        };

        MACnuToJ: MACnuToJ {
            compatible = "zmk,behavior-macro";
            #binding-cells = <0>;
            bindings =
                <&macro_tap>,
                <&to 1>,
                <&macro_press>,
                <&kp J>,
                <&macro_pause_for_release>,
                <&macro_release>,
                <&kp J>;

            label = "MACNUTOJ";
        };

        MACnuToM: MACnuToM {
            compatible = "zmk,behavior-macro";
            #binding-cells = <0>;
            bindings =
                <&macro_tap>,
                <&to 1>,
                <&macro_press>,
                <&kp M>,
                <&macro_pause_for_release>,
                <&macro_release>,
                <&kp M>;

            label = "MACNUTOM";
        };

        MACnuToH: MACnuToH {
            compatible = "zmk,behavior-macro";
            #binding-cells = <0>;
            bindings =
                <&macro_tap>,
                <&to 1>,
                <&macro_press>,
                <&kp H>,
                <&macro_pause_for_release>,
                <&macro_release>,
                <&kp H>;

            label = "MACNUTOH";
        };

        MACnuToN: MACnuToN {
            compatible = "zmk,behavior-macro";
            #binding-cells = <0>;
            bindings =
                <&macro_tap>,
                <&to 1>,
                <&macro_press>,
                <&kp N>,
                <&macro_pause_for_release>,
                <&macro_release>,
                <&kp N>;

            label = "MACNUTON";
        };

        MACnuToEsc: MACnuToEsc {
            compatible = "zmk,behavior-macro";
            #binding-cells = <0>;
            bindings =
                <&macro_tap>,
                <&to 1>,
                <&macro_press>,
                <&kp ESCAPE>,
                <&macro_pause_for_release>,
                <&macro_release>,
                <&kp ESCAPE>;

            label = "MACNUTOESC";
        };

        MACnuToA: MACnuToA {
            compatible = "zmk,behavior-macro";
            #binding-cells = <0>;
            bindings =
                <&macro_tap>,
                <&to 1>,
                <&macro_press>,
                <&kp A>,
                <&macro_pause_for_release>,
                <&macro_release>,
                <&kp A>;

            label = "MACNUTOA";
        };

        MACnuToZ: MACnuToZ {
            compatible = "zmk,behavior-macro";
            #binding-cells = <0>;
            bindings =
                <&macro_tap>,
                <&to 1>,
                <&macro_press>,
                <&kp Z>,
                <&macro_pause_for_release>,
                <&macro_release>,
                <&kp Z>;

            label = "MACNUTOZ";
        };

        MACnuToS: MACnuToS {
            compatible = "zmk,behavior-macro";
            #binding-cells = <0>;
            bindings =
                <&macro_tap>,
                <&to 1>,
                <&macro_press>,
                <&kp S>,
                <&macro_pause_for_release>,
                <&macro_release>,
                <&kp S>;

            label = "MACNUTOS";
        };

        MACnuToD: MACnuToD {
            compatible = "zmk,behavior-macro";
            #binding-cells = <0>;
            bindings =
                <&macro_tap>,
                <&to 1>,
                <&macro_press>,
                <&kp D>,
                <&macro_pause_for_release>,
                <&macro_release>,
                <&kp D>;

            label = "MACNUTOD";
        };

        MACnuToC: MACnuToC {
            compatible = "zmk,behavior-macro";
            #binding-cells = <0>;
            bindings =
                <&macro_tap>,
                <&to 1>,
                <&macro_press>,
                <&kp C>,
                <&macro_pause_for_release>,
                <&macro_release>,
                <&kp C>;

            label = "MACNUTOC";
        };

        MACnuToB: MACnuToB {
            compatible = "zmk,behavior-macro";
            #binding-cells = <0>;
            bindings =
                <&macro_tap>,
                <&to 1>,
                <&macro_press>,
                <&kp B>,
                <&macro_pause_for_release>,
                <&macro_release>,
                <&kp B>;

            label = "MACNUTOB";
        };

        MACnuToV: MACnuToV {
            compatible = "zmk,behavior-macro";
            #binding-cells = <0>;
            bindings =
                <&macro_tap>,
                <&to 1>,
                <&macro_press>,
                <&kp V>,
                <&macro_pause_for_release>,
                <&macro_release>,
                <&kp V>;

            label = "MACNUTOV";
        };

        MACnuToCtrlL: MACnuToCtrlL {
            compatible = "zmk,behavior-macro";
            #binding-cells = <0>;
            bindings =
                <&macro_tap>,
                <&to 1>,
                <&macro_press>,
                <&kp LCTRL>,
                <&macro_pause_for_release>,
                <&macro_release>,
                <&kp LCTRL>;

            label = "MACNUTOCTRLL";
        };

        MACnuToEnter: MACnuToEnter {
            compatible = "zmk,behavior-macro";
            #binding-cells = <0>;
            bindings =
                <&macro_tap>,
                <&to 1>,
                <&macro_press>,
                <&kp ENTER>,
                <&macro_pause_for_release>,
                <&macro_release>,
                <&kp ENTER>;

            label = "MACNUTOENTER";
        };

        MACnutoF: MACnutoF {
            compatible = "zmk,behavior-macro";
            #binding-cells = <0>;
            bindings =
                <&macro_tap>,
                <&to 1>,
                <&macro_press>,
                <&kp F>,
                <&macro_pause_for_release>,
                <&macro_release>,
                <&kp F>;

            label = "MACNUTOF";
        };

        MACnuTab: MACnuTab {
            compatible = "zmk,behavior-macro";
            #binding-cells = <0>;
            bindings =
                <&macro_tap>,
                <&to 1>,
                <&macro_press>,
                <&kp TAB>,
                <&macro_pause_for_release>,
                <&macro_release>,
                <&kp TAB>;

            label = "MACNUTAB";
        };

        MACnumToG: MACnumToG {
            compatible = "zmk,behavior-macro";
            #binding-cells = <0>;
            bindings =
                <&macro_tap>,
                <&to 1>,
                <&macro_press>,
                <&kp G>,
                <&macro_pause_for_release>,
                <&macro_release>,
                <&kp G>;

            label = "MACNUMTOG";
        };

        MACnumToX: MACnumToX {
            compatible = "zmk,behavior-macro";
            #binding-cells = <0>;
            bindings =
                <&macro_tap>,
                <&to 1>,
                <&macro_press>,
                <&kp X>,
                <&macro_pause_for_release>,
                <&macro_release>,
                <&kp X>;

            label = "MACNUMTOX";
        };

        CommandAndLayer: CommandAndLayer {
            compatible = "zmk,behavior-macro";
            #binding-cells = <0>;
            bindings =
                <&macro_tap>,
                <&to 1>,
                <&macro_press>,
                <&kp LEFT_GUI &mo 15>,
                <&macro_pause_for_release>,
                <&macro_release>,
                <&kp LEFT_GUI &mo 15>,
                <&macro_tap>,
                <&ToggleOffOnly 8>;

            label = "COMMANDANDLAYER";
            wait-ms = <1>;
        };

        MACCtrlAndLayerL: MACCtrlAndLayerL {
            compatible = "zmk,behavior-macro";
            #binding-cells = <0>;
            bindings =
                <&macro_tap>,
                <&to 1>,
                <&macro_press>,
                <&kp LCTRL &mo 18>,
                <&macro_pause_for_release>,
                <&macro_release>,
                <&kp LCTRL &mo 18>;

            label = "MACCTRLANDLAYERL";
            wait-ms = <1>;
        };

        MACNumToCtrlL: MACNumToCtrlL {
            compatible = "zmk,behavior-macro";
            #binding-cells = <0>;
            bindings =
                <&macro_tap>,
                <&to 1>,
                <&macro_press>,
                <&kp LCTRL>,
                <&macro_pause_for_release>,
                <&macro_release>,
                <&kp LCTRL>;

            label = "MACNUMTOCTRLL";
        };

        MACNumToCtrlR: MACNumToCtrlR {
            compatible = "zmk,behavior-macro";
            #binding-cells = <0>;
            bindings =
                <&macro_tap>,
                <&to 1>,
                <&macro_press>,
                <&kp RCTRL>,
                <&macro_pause_for_release>,
                <&macro_release>,
                <&kp RCTRL>;

            label = "MACNUMTOCTRLR";
        };

        MACNumToEsc: MACNumToEsc {
            compatible = "zmk,behavior-macro";
            #binding-cells = <0>;
            bindings =
                <&macro_tap>,
                <&to 1>,
                <&macro_press>,
                <&kp ESCAPE>,
                <&macro_pause_for_release>,
                <&macro_release>,
                <&kp ESCAPE>;

            label = "MACNUMTOESC";
        };

        TabThenTogArrow: TabThenTogArrow {
            compatible = "zmk,behavior-macro";
            #binding-cells = <0>;
            bindings = <&macro_press>, <&kp TAB>, <&macro_tap>, <&tog 7>;

            label = "TABTHENTOGARROW";
        };

        MACCropScreen: MACCropScreen {
            compatible = "zmk,behavior-macro";
            #binding-cells = <0>;
            bindings =
                <&macro_press>,
                <&kp LCTRL &kp LEFT_SHIFT &kp LEFT_GUI>,
                <&macro_tap>,
                <&kp NUMBER_4>,
                <&macro_release>,
                <&kp LCTRL &kp LEFT_SHIFT &kp LEFT_GUI>;

            label = "MACCROPSCREEN";
        };

        MACPictureFullScreen: MACPictureFullScreen {
            compatible = "zmk,behavior-macro";
            #binding-cells = <0>;
            bindings =
                <&macro_press>,
                <&kp LCTRL &kp LEFT_GUI &kp LEFT_SHIFT>,
                <&macro_tap>,
                <&kp NUMBER_3>,
                <&macro_release>,
                <&kp LCTRL &kp LEFT_GUI &kp LEFT_SHIFT>;

            label = "MACPICTUREFULLSCREEN";
        };

        MACCmdTab: MACWinTab {
            compatible = "zmk,behavior-macro";
            #binding-cells = <0>;
            bindings =
                <&macro_press>,
                <&kp LEFT_GUI>,
                <&macro_tap>,
                <&kp TAB>,
                <&macro_release>,
                <&kp LEFT_GUI>;

            label = "MACWINTAB";
        };

        MACCmdQ: MACCmdQ {
            compatible = "zmk,behavior-macro";
            #binding-cells = <0>;
            bindings =
                <&macro_press>,
                <&kp LEFT_GUI>,
                <&macro_tap>,
                <&kp Q>,
                <&macro_release>,
                <&kp LEFT_GUI>;

            label = "MACCMDQ";
        };

        TabToggleOnCursor: TabToggleOnCursor {
            compatible = "zmk,behavior-macro";
            #binding-cells = <0>;
            bindings =
                <&macro_press>,
                <&kp TAB &ToggleOnOnly 8>,
                <&macro_pause_for_release>,
                <&macro_release>,
                <&kp TAB &ToggleOnOnly 8>;

            label = "TABTOGGLEONCURSOR";
        };
    };

    keymap {
        compatible = "zmk,keymap";

        default_layer {
            display-name = "Default Layer";
            bindings = <
&kp GRAVE       &num_row NUMBER_1 Q  &num_row NUMBER_2 W  &num_row NUMBER_3 E  &num_row NUMBER_4 R  &num_row N5 T                                                                                                 &num_row NUMBER_6 Y  &num_row N7 U  &num_row N8 I  &num_row N9 O  &num_row N0 P  &kp BSPC
&kp TAB         &holdCtrlA 0 A       &holdCtrlS 0 S       &holdCtrlD 0 D       &holdCtrlF 0 F       &kp G                                                                                                         &kp H                &kp J          &kp K          &kp L          &kp SEMICOLON  &kp SQT
&kp LEFT_SHIFT  &holdCtrlZ 0 Z       &holdCtrlX 0 X       &holdCtrlC 0 C       &holdCtrlV 0 V       &holdCtrlB 0 B           &altAndlayer  &winAndlayer  &functionLayerTap 9 BACKSLASH  &symbolLayertap 10 ENTER  &kp N                &kp M          &kp COMMA      &kp DOT        &kp FSLH       &kp RIGHT_SHIFT
                                                                                                    &cursorLayerTap 6 MINUS  &lt 4 SPACE   &kp LCTRL     &kp RCTRL                      &kp SPACE                 &lt 11 EQUAL
            >;
        };

        MACLayer {
            display-name = "MacLayer";
            bindings = <
&kp GRAVE       &num_row NUMBER_1 Q   &num_row NUMBER_2 W   &num_row NUMBER_3 E   &num_row NUMBER_4 R   &num_row N5 T                                                                                                      &num_row NUMBER_6 Y  &num_row N7 U  &num_row N8 I  &num_row N9 O  &num_row N0 P  &kp BSPC
&kp TAB         &MACHoldCommandA 0 A  &MACHoldCommandS 0 S  &MACHoldCommandD 0 D  &MACHoldCommandF 0 F  &MACHoldCommandG 0 G                                                                                               &kp H                &kp J          &kp K          &kp L          &kp SEMICOLON  &kp SQT
&kp LEFT_SHIFT  &MACHoldCommandZ 0 Z  &MACHoldCommandX 0 X  &MACHoldCommandC 0 C  &MACHoldCommandV 0 V  &MACHoldCommandB 0 B     &kp LEFT_ALT  &CommandAndLayer   &functionLayerTap 9 BACKSLASH  &symbolLayertap 10 ENTER  &kp N                &kp M          &kp COMMA      &kp DOT        &kp FSLH       &kp RIGHT_SHIFT
                                                                                                        &cursorLayerTap 7 MINUS  &lt 4 SPACE   &MACCtrlAndLayerL  &kp RCTRL                      &kp SPACE                 &lt 11 EQUAL
            >;
        };

        number_row {
            bindings = <
&trans     &kp NUMBER_1  &kp N2   &kp N3   &kp N4   &kp N5                                                  &kp N6   &kp N7   &kp N8   &kp N9   &kp N0  &numToEsc
&numToTab  &numToA       &numToS  &numToD  &numToF  &numToG                                                 &numToH  &numToJ  &numToK  &numToL  &trans  &numToApostrophe
&trans     &numToZ       &numToX  &numToC  &numToV  &numToB  &trans  &trans       &trans       &numToEnter  &numToN  &numToM  &trans   &trans   &trans  &trans
                                                    &trans   &trans  &numToCtrlL  &numToCtrlR  &trans       &trans
            >;

            sensor-bindings = <&Scroll_D_U>, <&Scroll_RL>;
        };

        MACNumberRow {
            bindings = <
&trans     &kp NUMBER_1  &kp N2      &kp N3     &kp N4     &kp N5                                                             &kp N6     &kp N7     &kp N8     &kp N9     &kp N0  &MACnuToEsc
&MACnuTab  &MACnuToA     &MACnuToS   &MACnuToD  &MACnutoF  &MACnumToG                                                         &MACnuToH  &MACnuToJ  &MACnuToK  &MACnuToK  &trans  &trans
&trans     &MACnuToZ     &MACnumToX  &MACnuToC  &MACnuToV  &MACnuToB   &trans  &trans          &trans          &MACnuToEnter  &MACnuToN  &MACnuToM  &trans     &trans     &trans  &trans
                                                           &trans      &trans  &MACNumToCtrlL  &MACNumToCtrlR  &trans         &trans
            >;

            sensor-bindings = <&Scroll_D_U>, <&Scroll_RL>;
        };

        mouse_control {
            display-name = "mouse_control";
            bindings = <
&trans  &trans  &trans  &trans     &kp BACKSPACE  &trans                                     &zoomIn   &msc SCRL_DOWN  &mmv MOVE_UP    &msc SCRL_UP     &trans     &trans
&trans  &trans  &trans  &kp LCTRL  &kp ENTER      &trans                                     &zoomOut  &mmv MOVE_LEFT  &mmv MOVE_DOWN  &mmv MOVE_RIGHT  &mkp RCLK  &trans
&trans  &trans  &trans  &trans     &trans         &trans  &trans  &trans  &trans  &trans     &trans    &msc SCRL_LEFT  &mkp MCLK       &msc SCRL_RIGHT  &trans     &trans
                                                  &trans  &trans  &trans  &trans  &mkp LCLK  &trans
            >;

            sensor-bindings = <&Scroll_D_U>, <&Scroll_RL>;
        };

        MACMouseCotrol {
            display-name = "MACMouseCotrol";
            bindings = <
&trans  &trans  &trans  &trans        &kp BACKSPACE  &trans                                     &MACZoomIn   &msc SCRL_DOWN  &mmv MOVE_UP    &msc SCRL_UP     &trans     &trans
&trans  &trans  &trans  &kp LEFT_GUI  &kp ENTER      &trans                                     &MACZoomOut  &mmv MOVE_LEFT  &mmv MOVE_DOWN  &mmv MOVE_RIGHT  &mkp RCLK  &trans
&trans  &trans  &trans  &trans        &trans         &trans  &trans  &trans  &trans  &trans     &trans       &msc SCRL_LEFT  &mkp MCLK       &msc SCRL_RIGHT  &trans     &trans
                                                     &trans  &trans  &trans  &trans  &mkp LCLK  &trans
            >;

            sensor-bindings = <&Scroll_D_U>, <&Scroll_RL>;
        };

        cursor_layer {
            display-name = "cursor_layer";
            bindings = <
&trans  &trans  &trans  &trans     &trans          &trans                                         &kp HOME   &kp ENTER       &kp UP_ARROW    &kp BACKSPACE    &trans      &trans
&trans  &trans  &trans  &kp LCTRL  &kp LEFT_SHIFT  &trans                                         &kp END    &kp LEFT_ARROW  &kp DOWN_ARROW  &kp RIGHT_ARROW  &shift_f10  &trans
&trans  &trans  &trans  &kp ENTER  &kp BACKSPACE   &trans  &trans  &trans  &kp DELETE  &kp ENTER  &trans     &trans          &trans          &trans           &trans      &trans
                                                   &trans  &trans  &trans  &trans      &kp SPACE  &kp ENTER
            >;

            sensor-bindings =
                <&inc_dec_kp DOWN UP_ARROW>,
                <&inc_dec_kp RIGHT LEFT>;
        };

        MacCursorlayer {
            display-name = "MacCursorlayer";
            bindings = <
&trans  &trans  &trans  &trans        &trans          &trans                                         &kp HOME   &kp ENTER       &kp UP_ARROW    &kp BACKSPACE    &trans      &trans
&trans  &trans  &trans  &kp LEFT_ALT  &kp LEFT_SHIFT  &trans                                         &kp END    &kp LEFT_ARROW  &kp DOWN_ARROW  &kp RIGHT_ARROW  &shift_f10  &trans
&trans  &trans  &trans  &kp ENTER     &kp BACKSPACE   &trans  &trans  &trans  &kp DELETE  &kp ENTER  &trans     &trans          &trans          &trans           &trans      &trans
                                                      &trans  &trans  &trans  &trans      &kp SPACE  &kp ENTER
            >;

            sensor-bindings =
                <&inc_dec_kp DOWN UP_ARROW>,
                <&inc_dec_kp RIGHT LEFT>;
        };

        MACCmdTabCursor {
            display-name = "MacCursorlayer";
            bindings = <
&trans  &trans  &trans  &trans        &trans          &trans                                         &kp HOME   &kp ENTER       &kp UP_ARROW    &kp BACKSPACE    &trans      &trans
&trans  &trans  &trans  &kp LEFT_ALT  &kp LEFT_SHIFT  &trans                                         &kp END    &kp LEFT_ARROW  &kp DOWN_ARROW  &kp RIGHT_ARROW  &shift_f10  &trans
&trans  &trans  &trans  &kp ENTER     &kp BACKSPACE   &trans  &trans  &trans  &kp DELETE  &kp ENTER  &trans     &trans          &trans          &trans           &trans      &trans
                                                      &trans  &trans  &trans  &kp ESCAPE  &kp SPACE  &kp ENTER
            >;

            sensor-bindings =
                <&inc_dec_kp DOWN UP_ARROW>,
                <&inc_dec_kp RIGHT LEFT>;
        };

        function_layer {
            bindings = <
&trans  &kp F1  &kp F2   &kp F3   &kp F4   &kp F5                                          &trans  &trans  &trans  &trans  &trans  &trans
&trans  &kp F6  &kp F7   &kp F8   &kp F9   &F10WinB 0 F10                                  &trans  &trans  &trans  &trans  &trans  &trans
&trans  &trans  &kp F13  &kp F11  &kp F12  &winB           &trans  &trans  &trans  &trans  &trans  &trans  &trans  &trans  &trans  &trans
                                           &trans          &trans  &trans  &trans  &trans  &trans
            >;
        };

        symbol {
            bindings = <
&trans  &kp EXCL  &kp AT     &kp HASH        &kp DOLLAR       &kp PERCENT                                    &kp PLUS  &kp MINUS  &kp LEFT_PARENTHESIS  &kp RIGHT_PARENTHESIS  &trans  &trans
&trans  &trans    &kp CARET  &kp LEFT_BRACE  &kp RIGHT_BRACE  &kp AMPERSAND                                  &trans    &trans     &kp LEFT_BRACKET      &kp RIGHT_BRACKET      &trans  &trans
&trans  &trans    &trans     &kp ASTERISK    &kp SLASH        &trans         &trans  &trans  &trans  &trans  &trans    &trans     &trans                &trans                 &trans  &trans
                                                              &trans         &trans  &trans  &trans  &trans  &trans
            >;
        };

        setting_layer {
            bindings = <
&trans  &kp C_VOLUME_DOWN  &kp C_VOLUME_UP  &kp C_BRIGHTNESS_DEC  &kp C_BRIGHTNESS_INC  &kp PRINTSCREEN                                  &kp HOME  &kp ENTER       &kp UP_ARROW    &kp BACKSPACE    &trans      &trans
&trans  &trans             &trans           &kp LCTRL             &kp LEFT_SHIFT        &trans                                           &kp END   &kp LEFT_ARROW  &kp DOWN_ARROW  &kp RIGHT_ARROW  &shift_f10  &trans
&trans  &kp C_MUTE         &trans           &trans                &trans                &trans           &trans  &trans  &trans  &trans  &trans    &kp SPACE       &trans          &trans           &trans      &trans
                                                                                        &trans           &trans  &trans  &trans  &trans  &trans
            >;
        };

        MACSettingLayer {
            bindings = <
&trans  &kp C_VOLUME_DOWN  &kp C_VOLUME_UP  &kp C_BRIGHTNESS_DEC  &kp C_BRIGHTNESS_INC  &MACCropScreen                                         &kp HOME  &kp ENTER       &kp UP_ARROW    &kp BACKSPACE    &trans      &trans
&trans  &trans             &trans           &kp LEFT_ALT          &kp LEFT_SHIFT        &MACPictureFullScreen                                  &kp END   &kp LEFT_ARROW  &kp DOWN_ARROW  &kp RIGHT_ARROW  &shift_f10  &trans
&trans  &kp C_MUTE         &trans           &trans                &trans                &trans                 &trans  &trans  &trans  &trans  &trans    &kp SPACE       &trans          &trans           &trans      &trans
                                                                                        &trans                 &trans  &trans  &trans  &trans  &trans
            >;
        };

        kbMouse {
            bindings = <
&trans  &trans  &trans  &trans  &trans  &trans                                  &trans  &trans  &trans  &trans  &trans  &trans
&trans  &ctrlZ  &ctrlX  &ctrlC  &ctrlV  &ctrlY                                  &trans  &trans  &trans  &trans  &trans  &trans
&trans  &trans  &trans  &trans  &trans  &trans  &trans  &trans  &trans  &trans  &trans  &trans  &trans  &trans  &trans  &trans
                                        &trans  &trans  &trans  &trans  &trans  &trans
            >;
        };

        window_navi {
            bindings = <
&trans  &trans  &trans  &kp TAB  &kp TAB  &trans                                  &trans  &trans          &kp UP_ARROW    &trans           &trans  &trans
&trans  &trans  &trans  &trans   &trans   &winB                                   &trans  &kp LEFT_ARROW  &kp DOWN_ARROW  &kp RIGHT_ARROW  &trans  &trans
&trans  &trans  &trans  &trans   &trans   &trans  &trans  &trans  &trans  &trans  &trans  &trans          &trans          &trans           &trans  &trans
                                          &trans  &trans  &trans  &trans  &trans  &trans
            >;
        };

        Command_navi {
            bindings = <
&trans  &trans  &trans  &TabToggleOnCursor  &TabToggleOnCursor  &trans                                  &trans  &trans  &trans  &trans  &trans  &trans
&trans  &trans  &trans  &trans              &trans              &trans                                  &trans  &trans  &trans  &trans  &trans  &trans
&trans  &trans  &trans  &trans              &trans              &trans  &trans  &trans  &trans  &trans  &trans  &trans  &trans  &trans  &trans  &trans
                                                                &trans  &trans  &trans  &trans  &trans  &trans
            >;
        };

        alt_navi {
            bindings = <
&trans  &trans  &kp TAB  &kp TAB  &kp F4  &trans                                  &trans  &trans          &kp UP_ARROW    &trans           &trans  &trans
&trans  &trans  &trans   &trans   &trans  &trans                                  &trans  &kp LEFT_ARROW  &kp DOWN_ARROW  &kp RIGHT_ARROW  &trans  &trans
&trans  &trans  &trans   &trans   &trans  &trans  &trans  &trans  &trans  &trans  &trans  &trans          &trans          &trans           &trans  &trans
                                          &trans  &trans  &trans  &trans  &trans  &trans
            >;
        };

        MACOptionNavi {
            bindings = <
&trans  &trans  &MACCmdTab  &MACCmdTab  &MACCmdQ  &trans                                  &trans  &trans  &trans  &trans  &trans  &trans
&trans  &trans  &trans      &trans      &trans    &trans                                  &trans  &trans  &trans  &trans  &trans  &trans
&trans  &trans  &trans      &trans      &trans    &trans  &trans  &trans  &trans  &trans  &trans  &trans  &trans  &trans  &trans  &trans
                                                  &trans  &trans  &trans  &trans  &trans  &trans
            >;
        };

        MACCtrlNavi {
            bindings = <
&trans  &trans  &trans  &trans  &trans  &trans                                  &trans  &trans          &kp UP_ARROW    &trans           &trans  &trans
&trans  &trans  &trans  &trans  &trans  &trans                                  &trans  &kp LEFT_ARROW  &kp DOWN_ARROW  &kp RIGHT_ARROW  &trans  &trans
&trans  &trans  &trans  &trans  &trans  &trans  &trans  &trans  &trans  &trans  &trans  &trans          &trans          &trans           &trans  &trans
                                        &trans  &trans  &trans  &trans  &trans  &trans
            >;
        };

        OxygenNotIncludedLayer {
            bindings = <
&trans  &kp TAB    &kp Q  &kp W  &kp E  &kp R                                      &trans  &trans  &trans  &trans  &trans  &trans
&trans  &kp LSHFT  &kp A  &kp S  &kp D  &kp F                                      &trans  &trans  &trans  &trans  &trans  &trans
&trans  &trans     &kp Z  &kp X  &kp C  &kp V   &trans     &trans  &trans  &trans  &trans  &trans  &trans  &trans  &trans  &trans
                                        &trans  &kp SPACE  &trans  &trans  &trans  &trans
            >;

            sensor-bindings = <&Scroll_D_U>, <&Scroll_RL>;
        };

        CursorLayer {
            bindings = <
&trans  &trans  &trans  &trans  &trans  &trans                                  &trans  &trans  &trans  &trans    &trans    &tog 20
&trans  &trans  &trans  &trans  &trans  &trans                                  &trans  &trans  &trans  &trans    &kp UP    &kp RIGHT
&trans  &trans  &trans  &trans  &trans  &trans  &trans  &trans  &trans  &trans  &trans  &trans  &trans  &kp LEFT  &kp DOWN  &tog 20
                                        &trans  &trans  &trans  &trans  &trans  &trans
            >;
        };

        onekeyboardControl {
            bindings = <
&trans  &trans  &trans  &trans  &trans  &trans                                        &trans  &trans  &trans  &trans          &mmv MOVE_UP    &msc SCRL_RIGHT
&trans  &trans  &trans  &trans  &trans  &trans                                        &trans  &trans  &trans  &msc SCRL_LEFT  &mmv MOVE_DOWN  &mmv MOVE_RIGHT
&trans  &trans  &trans  &trans  &trans  &trans  &trans  &trans  &kp RCTRL  &mkp LCLK  &trans  &trans  &trans  &mmv MOVE_LEFT  &msc SCRL_DOWN  &msc SCRL_UP
                                        &trans  &trans  &trans  &trans     &mkp RCLK  &trans
            >;

            sensor-bindings = <&Scroll_D_U>, <&Scroll_RL>;
        };

        general_gaming_layer {
            bindings = <
&trans  &kp TAB    &kp Q  &kp W  &kp E  &kp R                                      &trans  &trans  &trans  &trans  &trans  &trans
&trans  &kp LSHFT  &kp A  &kp S  &kp D  &kp F                                      &trans  &trans  &trans  &trans  &trans  &trans
&trans  &trans     &kp Z  &kp X  &kp C  &kp V   &trans     &trans  &trans  &trans  &trans  &trans  &trans  &trans  &trans  &trans
                                        &trans  &kp SPACE  &trans  &trans  &trans  &trans
            >;

            sensor-bindings = <&Scroll_D_U>, <&Scroll_RL>;
        };

        gaming1st_person {
            bindings = <
&trans  &kp TAB    &kp Q  &kp W  &kp E  &kp R                                         &trans  &msc SCRL_DOWN  &kp Y           &msc SCRL_UP  &trans     &trans
&trans  &kp LSHFT  &kp A  &kp S  &kp D  &kp F                                         &trans  &kp G           &mmv MOVE_DOWN  &kp J         &mkp RCLK  &trans
&trans  &trans     &kp Z  &kp X  &kp C  &kp V   &trans     &trans  &trans  &trans     &trans  &trans          &trans          &trans        &trans     &trans
                                        &trans  &kp SPACE  &trans  &trans  &mkp LCLK  &trans
            >;

            sensor-bindings = <&Scroll_D_U>, <&Scroll_RL>;
        };

        bluetoothSettingLayer {
            bindings = <
&trans  &bt BT_SEL 1  &bt BT_SEL 2  &bt BT_SEL 3  &bt BT_SEL 4  &bt BT_SEL 0                                  &trans  &trans  &trans  &trans  &trans  &trans
&trans  &trans        &trans        &trans        &trans        &trans                                        &trans  &trans  &trans  &trans  &trans  &trans
&trans  &trans        &trans        &trans        &trans        &trans        &trans  &trans  &trans  &trans  &trans  &trans  &trans  &trans  &trans  &trans
                                                                &trans        &trans  &trans  &trans  &trans  &trans
            >;
        };
    };
};
